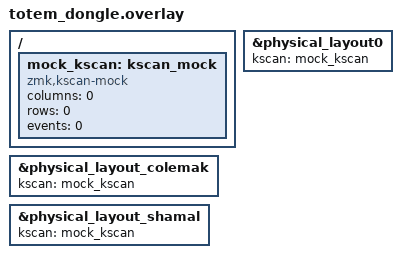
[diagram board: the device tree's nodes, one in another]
/*
 * Copyright (c) 2022 The ZMK Contributors
 *
 * SPDX-License-Identifier: MIT
 */

#include "totem.dtsi"

/ {
    mock_kscan: kscan_mock {
        compatible = "zmk,kscan-mock";
        columns = <0>;
        rows = <0>;
        events = <0>;
    };
};

&physical_layout0 {
    kscan = <&mock_kscan>;
};

&physical_layout_colemak {
    kscan = <&mock_kscan>;
};

&physical_layout_shamal {
    kscan = <&mock_kscan>;
};

/delete-node/ &kscan0;
